# CY8C5888LTQ_LP097 register map
File version: 0.1
Registers are 8-bit, read-write, no defined reset value unless marked. A register's access mark holds for its fields unless they carry their own. Offsets are from the block's base; [hi:lo] are bit positions; 'fields as' and 'values as' point back to an identical list.

## Engine_Mode_FL
Base 0x00000000
0x40006579 Engine_Mode_FL_CONTROL_REG

## XBee — UART
Base 0x00000000
0x40006428 RX_XBee_RX_ADDRESS1 — RX Address1 Register
0x40006438 RX_XBee_RX_ADDRESS2 — RX Address2 Register
0x40006448 RX_XBee_RX_DATA — RX Data Register
0x4000644B TX_XBee_TX_DATA — TX Data Register
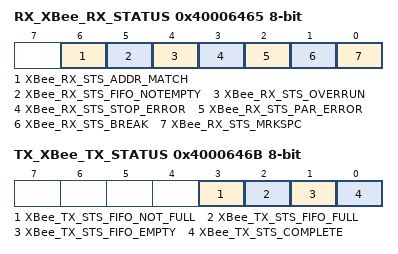
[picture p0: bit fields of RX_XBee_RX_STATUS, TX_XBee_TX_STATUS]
0x40006465 RX_XBee_RX_STATUS — RX status register
  [6] XBee_RX_STS_ADDR_MATCH ro, [5] XBee_RX_STS_FIFO_NOTEMPTY ro, [4] XBee_RX_STS_OVERRUN ro, [3] XBee_RX_STS_STOP_ERROR ro, [2] XBee_RX_STS_PAR_ERROR ro, [1] XBee_RX_STS_BREAK ro, [0] XBee_RX_STS_MRKSPC ro
0x4000646B TX_XBee_TX_STATUS — TX status register
  [3] XBee_TX_STS_FIFO_NOT_FULL ro, [2] XBee_TX_STS_FIFO_FULL ro, [1] XBee_TX_STS_FIFO_EMPTY ro, [0] XBee_TX_STS_COMPLETE ro

## Engine_Mode_RL
Base 0x00000000
0x40006577 Engine_Mode_RL_CONTROL_REG

## Engine_PWM_Rear
Base 0x00000000
0x40006528 Engine_PWM_Rear_COMPARE_1 16-bit — UDB.D0 - Assigned Compare1 Value
0x40006538 Engine_PWM_Rear_COMPARE_2 16-bit — UDB.D1 - Assigned Compare2 Value
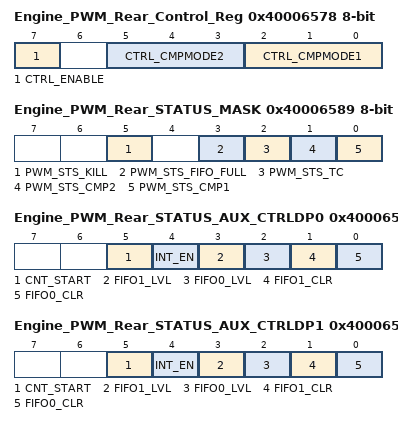
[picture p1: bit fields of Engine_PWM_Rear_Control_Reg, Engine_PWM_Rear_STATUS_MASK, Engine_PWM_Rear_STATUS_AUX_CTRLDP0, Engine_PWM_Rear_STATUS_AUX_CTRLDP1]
0x40006578 Engine_PWM_Rear_Control_Reg — UDB Control Register - Assigned Control Register Value
  [7] CTRL_ENABLE — Enable the PWM
  [5:3] CTRL_CMPMODE2 — Compare mode 2
  [2:0] CTRL_CMPMODE1 — Compare mode 1
0x40006589 Engine_PWM_Rear_STATUS_MASK — UDB Status bits Interrupt Mask Enable Register
  [5] PWM_STS_KILL ro — Enables the Interrupt on Kill
  [3] PWM_STS_FIFO_FULL ro — FIFO Full Status Mask
  [2] PWM_STS_TC ro — Enables the Interrupt on Terminal Count
  [1] PWM_STS_CMP2 ro — Enables the Interrupt on Compare 2
  [0] PWM_STS_CMP1 ro — Enables the Interrupt on Compare 1
0x40006598 Engine_PWM_Rear_STATUS_AUX_CTRLDP0 — UDB Auxilliary Control Register
  [5] CNT_START — FIFO0 clear
    0=E_CNT_START0 (Disable counter); 1=E_CNT_START1 (Enable counter)
  [4] INT_EN
    0=E_INT_EN0 (Interrupt disabled); 1=E_INT_EN1 (Interrupt enabled)
  [3] FIFO1_LVL — FIFO level
    0=E_FIFO_LVL_0 (FIFO LVL: input mode: FIFO not full; output mode: FIFO not empty); 1=E_FIFO_LVL_1 (FIFO LVL: input mode: FIFO at least 1/2 empty; output mode: FIFO at least 1/2 full)
  [2] FIFO0_LVL — FIFO level
    values as FIFO1_LVL
  [1] FIFO1_CLR — FIFO1 clear
    0=E_FIFO_CLR_0 (Normal FIFO operation); 1=E_FIFO_CLR_1 (Clear FIFO state)
  [0] FIFO0_CLR — FIFO0 clear
    values as FIFO1_CLR
0x40006599 Engine_PWM_Rear_STATUS_AUX_CTRLDP1 — UDB Auxilliary Control Register
  fields as Engine_PWM_Rear_STATUS_AUX_CTRLDP0

## UART_LOG — UART
Base 0x00000000
0x4000644E TX_UART_LOG_TX_DATA — TX Data Register
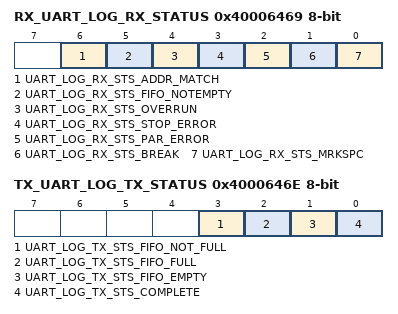
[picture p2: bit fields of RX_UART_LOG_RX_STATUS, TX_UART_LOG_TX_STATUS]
0x40006469 RX_UART_LOG_RX_STATUS — RX status register
  [6] UART_LOG_RX_STS_ADDR_MATCH ro, [5] UART_LOG_RX_STS_FIFO_NOTEMPTY ro, [4] UART_LOG_RX_STS_OVERRUN ro, [3] UART_LOG_RX_STS_STOP_ERROR ro, [2] UART_LOG_RX_STS_PAR_ERROR ro, [1] UART_LOG_RX_STS_BREAK ro, [0] UART_LOG_RX_STS_MRKSPC ro
0x4000646E TX_UART_LOG_TX_STATUS — TX status register
  [3] UART_LOG_TX_STS_FIFO_NOT_FULL ro, [2] UART_LOG_TX_STS_FIFO_FULL ro, [1] UART_LOG_TX_STS_FIFO_EMPTY ro, [0] UART_LOG_TX_STS_COMPLETE ro
0x4000652A RX_UART_LOG_RX_ADDRESS1 — RX Address1 Register
0x4000653A RX_UART_LOG_RX_ADDRESS2 — RX Address2 Register
0x4000654A RX_UART_LOG_RX_DATA — RX Data Register

## Engine_PWM_Front
Base 0x00000000
0x4000642C Engine_PWM_Front_COMPARE_1 16-bit — UDB.D0 - Assigned Compare1 Value
0x4000643C Engine_PWM_Front_COMPARE_2 16-bit — UDB.D1 - Assigned Compare2 Value
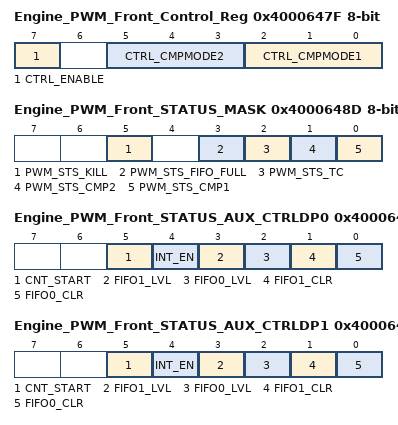
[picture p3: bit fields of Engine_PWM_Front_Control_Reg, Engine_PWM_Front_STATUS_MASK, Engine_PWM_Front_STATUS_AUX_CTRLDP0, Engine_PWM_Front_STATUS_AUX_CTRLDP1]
0x4000647F Engine_PWM_Front_Control_Reg — UDB Control Register - Assigned Control Register Value
  [7] CTRL_ENABLE — Enable the PWM
  [5:3] CTRL_CMPMODE2 — Compare mode 2
  [2:0] CTRL_CMPMODE1 — Compare mode 1
0x4000648D Engine_PWM_Front_STATUS_MASK — UDB Status bits Interrupt Mask Enable Register
  [5] PWM_STS_KILL ro — Enables the Interrupt on Kill
  [3] PWM_STS_FIFO_FULL ro — FIFO Full Status Mask
  [2] PWM_STS_TC ro — Enables the Interrupt on Terminal Count
  [1] PWM_STS_CMP2 ro — Enables the Interrupt on Compare 2
  [0] PWM_STS_CMP1 ro — Enables the Interrupt on Compare 1
0x4000649C Engine_PWM_Front_STATUS_AUX_CTRLDP0 — UDB Auxilliary Control Register
  [5] CNT_START — FIFO0 clear
    0=E_CNT_START0 (Disable counter); 1=E_CNT_START1 (Enable counter)
  [4] INT_EN
    0=E_INT_EN0 (Interrupt disabled); 1=E_INT_EN1 (Interrupt enabled)
  [3] FIFO1_LVL — FIFO level
    0=E_FIFO_LVL_0 (FIFO LVL: input mode: FIFO not full; output mode: FIFO not empty); 1=E_FIFO_LVL_1 (FIFO LVL: input mode: FIFO at least 1/2 empty; output mode: FIFO at least 1/2 full)
  [2] FIFO0_LVL — FIFO level
    values as FIFO1_LVL
  [1] FIFO1_CLR — FIFO1 clear
    0=E_FIFO_CLR_0 (Normal FIFO operation); 1=E_FIFO_CLR_1 (Clear FIFO state)
  [0] FIFO0_CLR — FIFO0 clear
    values as FIFO1_CLR
0x4000649D Engine_PWM_Front_STATUS_AUX_CTRLDP1 — UDB Auxilliary Control Register
  fields as Engine_PWM_Front_STATUS_AUX_CTRLDP0

## Engine_Mode_RR
Base 0x00000000
0x40006575 Engine_Mode_RR_CONTROL_REG

## Engine_Mode_FR
Base 0x00000000
0x40006576 Engine_Mode_FR_CONTROL_REG
